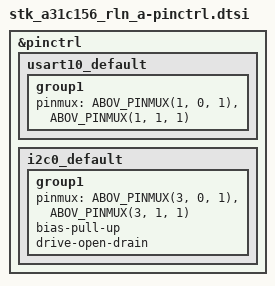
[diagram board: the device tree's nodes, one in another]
/*
 * Copyright (c) 2026 ABOV Semiconductor Co., Ltd.
 * SPDX-License-Identifier: BSD-3-Clause
 */

#include <zephyr/dt-bindings/pinctrl/abov-pinctrl.h>

&pinctrl {
	/*
	 * USART10 Pin Configuration (PB0: TX, PB1: RX, ALT1), per the default
	 * debug console pin mapping in debug_a31c15x.h (DEBUG_UART_ID=0,
	 * DEBUG_PORT_ID=1/PORT B, TX pin 0, RX pin 1, ALT 1).
	 */
	usart10_default: usart10_default {
		group1 {
			pinmux = <ABOV_PINMUX(1, 0, 1)>, /* PB0 - USART10_TX (ALT1) */
				 <ABOV_PINMUX(1, 1, 1)>; /* PB1 - USART10_RX (ALT1) */
		};
	};

	/* I2C0 Pin Configuration (PD0: SCL, PD1: SDA, ALT1) */
	i2c0_default: i2c0_default {
		group1 {
			pinmux = <ABOV_PINMUX(3, 0, 1)>, /* PD0 - I2C0_SCL (ALT1) */
				 <ABOV_PINMUX(3, 1, 1)>; /* PD1 - I2C0_SDA (ALT1) */
			bias-pull-up;
			drive-open-drain;
		};
	};
};
